# GD32H71x_72x register map
File version: 1.0
CPU: CM7 r1p2, little endian, MPU, FPU, 4 interrupt priority bits
Registers are 32-bit, read-write, reset 0x0 unless marked. A register's access mark holds for its fields unless they carry their own. Offsets are from the block's base; [hi:lo] are bit positions; {n}, {i} and the like mark numbered series; 'fields as' and 'values as' point back to an identical list.

## TRNG — True random number generator
Base 0x48021800
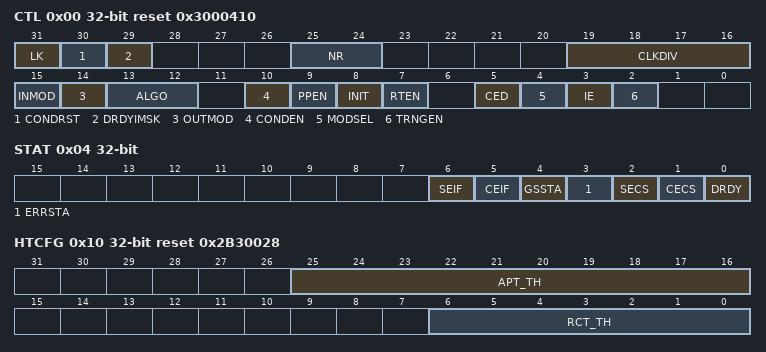
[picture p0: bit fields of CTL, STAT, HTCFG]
0x00 CTL reset 0x3000410 — Control register
  [31] LK — TRNG_CTL[28:4] and TRNG_HTCFG register lock bit
  [30] CONDRST — Reset conditioning logic
  [29] DRDYIMSK — DRDY interrupt mask bit. This bit can mask the interrupt generated because DRDY is set.
  [25:24] NR — Analog trng power mode
  [19:16] CLKDIV — TRNG clock divider
  [15] INMOD — Select random seed number input to conditioning module
  [14] OUTMOD — Select random data width output of conditioning module
  [13:12] ALGO — conditioning module hash algorithm selection
  [10] CONDEN — The enable bit of conditioning component
  [9] PPEN — The enable bit of post_processing function
  [8] INIT — Initialize hash algorithm when conditioning enabled.
  [7] RTEN — Replace test enable bit
  [5] CED — Clock error detection
  [4] MODSEL — LFSR or NIST mode selection
  [3] IE — The enable bit of the TRNG interrupt. This bit controls the generation of an interrupt when DRDY, SEIF CEIF or ERRSTA was set.
  [2] TRNGEN — The enabled bit of the TRNG.
0x04 STAT access per field — Status register
  [6] SEIF rw — Seed error interrupt flag
  [5] CEIF rw — Clock error interrupt flag
  [4] GSSTA ro — This bit indicates whether condition stage is in generating random number sample state, when the startup health test has been completed.
  [3] ERRSTA ro — NIST mode error status, this bit could be reset by CONDRST
  [2] SECS ro — Seed error current status
  [1] CECS ro — Clock error current status
  [0] DRDY ro — Random data ready status bit. This bit is cleared by reading the TRNG_DATA register and set when a new random number is generated.
0x08 DATA ro
  [31:0] TRNDATA — 32-bit random data
0x10 HTCFG reset 0x2B30028 — Health tests configure register
  [25:16] APT_TH — Adaptive proportion test threshold. Default 691.
  [6:0] RCT_TH — Repetition count test threshold. Default 40.

## USBFS_HOST — USB on the go full speed host
Base 0x40080400
0x00 HCTL — host configuration register (HCTL)
  [1:0] CLKSEL — clock select for USB clock
0x04 HFT reset 0xBB80 — Host frame interval register
  [15:0] FRI — Frame interval
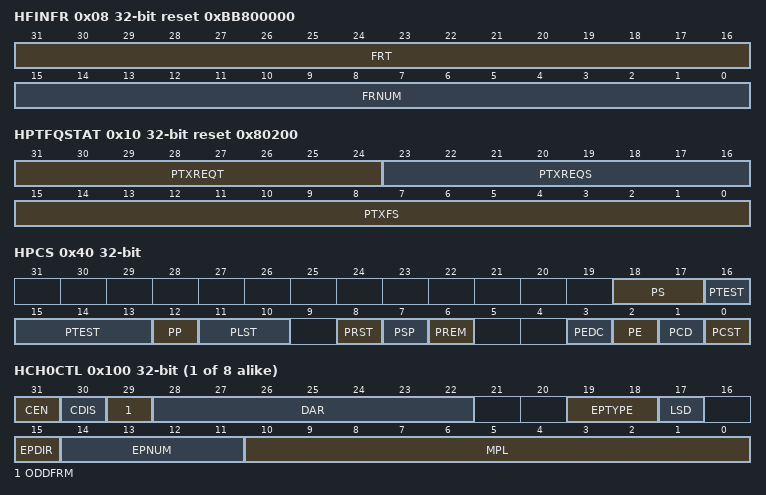
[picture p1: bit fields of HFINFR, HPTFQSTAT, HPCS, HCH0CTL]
0x08 HFINFR ro reset 0xBB800000 — OTG_FS host frame number/frame time remaining register (HFINFR)
  [31:16] FRT — Frame remaining time
  [15:0] FRNUM — Frame number
0x10 HPTFQSTAT ro reset 0x80200 — Host periodic transmit FIFO/queue status register (HPTFQSTAT)
  [31:24] PTXREQT — Top of the periodic transmit request queue
  [23:16] PTXREQS — Periodic transmit request queue space available
  [15:0] PTXFS — Periodic transmit data FIFO space available
0x14 HACHINT ro — Host all channels interrupt register
  [7:0] HACHINT — Host all channel interrupts
0x18 HACHINTEN — host all channels interrupt mask register
  [7:0] CINTEN — Channel interrupt enable
0x40 HPCS access per field — Host port control and status register (USBFS_HPCS)
  [18:17] PS ro — Port speed
  [16:13] PTEST rw — Port Test control
  [12] PP rw — Port power
  [11:10] PLST ro — Port line status
  [8] PRST rw — Port reset
  [7] PSP rw — Port suspend
  [6] PREM rw — Port resume
  [3] PEDC rw — Port enable/disable change
  [2] PE rw — Port enable
  [1] PCD rw — Port connect detected
  [0] PCST ro — Port connect status
{0x100+0x20*i} HCH{i}CTL (i=0..7) — host channel-{i} characteristics register (HCH{i}CTL)
  [31] CEN — Channel enable
  [30] CDIS — Channel disable
  [29] ODDFRM — Odd frame
  [28:22] DAR — Device address
  [19:18] EPTYPE — Endpoint type
  [17] LSD — Low-speed device
  [15] EPDIR — Endpoint direction
  [14:11] EPNUM — Endpoint number
  [10:0] MPL — Maximum packet size
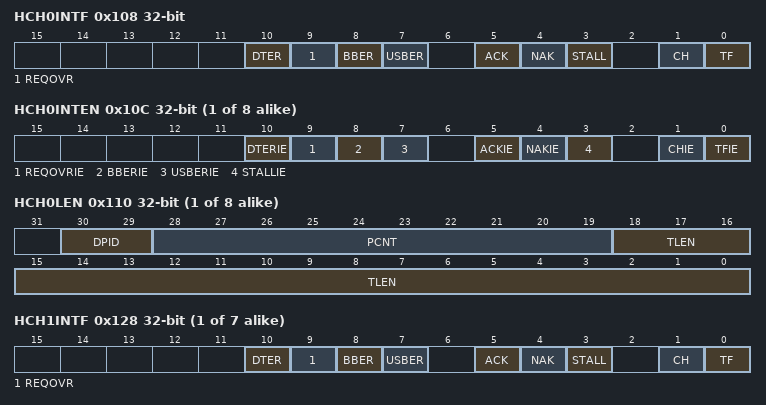
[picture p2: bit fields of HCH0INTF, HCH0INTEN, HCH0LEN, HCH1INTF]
0x108 HCH0INTF — host channel-0 interrupt register (USBFS_HCHxINTF)
  [10] DTER — Data toggle error
  [9] REQOVR — Request queue overrun
  [8] BBER — Babble error
  [7] USBER — USB bus error
  [5] ACK — ACK response received/transmitted interrupt
  [4] NAK — NAK response received interrupt
  [3] STALL — STALL response received interrupt
  [1] CH — Channel halted
  [0] TF — Transfer finished
{0x10C+0x20*i} HCH{i}INTEN (i=0..7) — host channel-{i} interrupt enable register (HCH{i}INTEN)
  [10] DTERIE — Data toggle error interrupt enable
  [9] REQOVRIE — request queue overrun interrupt enable
  [8] BBERIE — Babble error interrupt enable
  [7] USBERIE — USB bus error interrupt enable
  [5] ACKIE — ACK interrupt enable
  [4] NAKIE — NAK interrupt enable
  [3] STALLIE — STALL interrupt enable
  [1] CHIE — Channel halted interrupt enable
  [0] TFIE — Transfer completed interrupt enable
{0x110+0x20*i} HCH{i}LEN (i=0..7) — host channel-{i} transfer length register
  [30:29] DPID — Data PID
  [28:19] PCNT — Packet count
  [18:0] TLEN — Transfer length
{0x108+0x20*i} HCH{i}INTF (i=1..7) — host channel-{i} interrupt register (HCH{i}INTF)
  fields as HCH0INTF

## USBFS_PWRCLK — USB on the go full speed
Base 0x40080E00
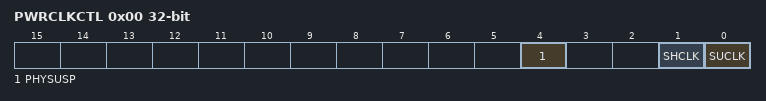
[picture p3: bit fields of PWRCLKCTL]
0x00 PWRCLKCTL — power and clock gating control register (PWRCLKCTL)
  [4] PHYSUSP — PHY suspend status
  [1] SHCLK — Stop HCLK
  [0] SUCLK — Stop the USB clock

## USBHS_PWRCLK — USB on the go high speed
Base 0x40040E00
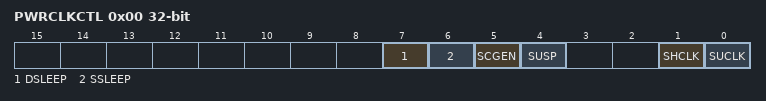
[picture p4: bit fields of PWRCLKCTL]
0x00 PWRCLKCTL access per field — power and clock gating control register (PWRCLKCTL)
  [7] DSLEEP ro — PHY is in deep sleep status
  [6] SSLEEP ro — PHY is in shallow sleep status
  [5] SCGEN ro — internal clock gating enable
  [4] SUSP ro — PHY is in suspend status
  [1] SHCLK rw — Stop HCLK
  [0] SUCLK rw — Stop the USB clock

## VREF
Base 0x58003C00
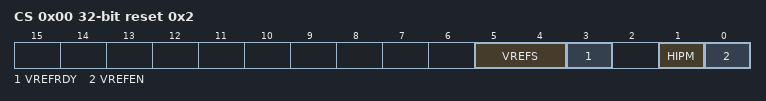
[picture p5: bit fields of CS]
0x00 CS access per field reset 0x2 — Control and status register
  [5:4] VREFS rw — Voltage reference select
  [3] VREFRDY ro — VREF ready
  [1] HIPM rw — High impedance mode
  [0] VREFEN rw — VREF enable
0x04 CALIB — Calibration register
  [5:0] VREFCAL — VREF calibration

## WWDGT — Window watchdog timer
Base 0x58004C00
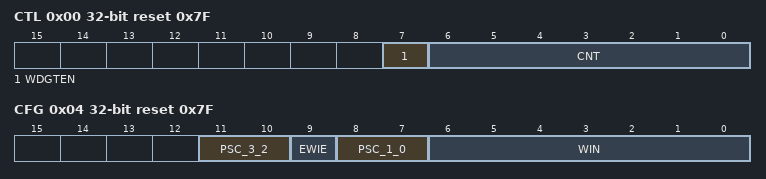
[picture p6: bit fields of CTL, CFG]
0x00 CTL reset 0x7F — Control register
  [7] WDGTEN — Activation bit
  [6:0] CNT — 7-bit counter
0x04 CFG reset 0x7F — Configuration register
  [11:10] PSC_3_2 — High bit value of prescaler
  [9] EWIE — Early wakeup interrupt
  [8:7] PSC_1_0 — Prescaler
  [6:0] WIN — 7-bit window value
0x08 STAT — Status register
  [0] EWIF — Early wakeup interrupt flag
